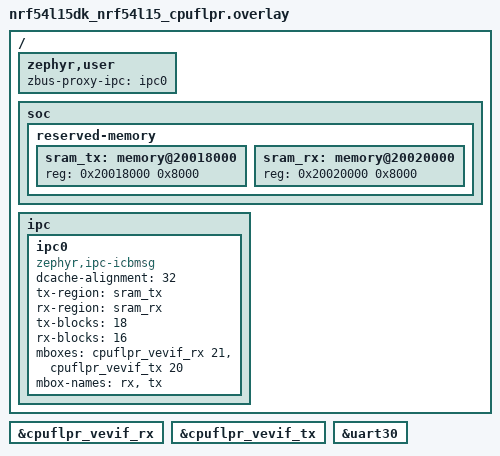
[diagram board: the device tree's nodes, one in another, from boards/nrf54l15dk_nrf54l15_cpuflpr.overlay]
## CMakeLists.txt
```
#
# Copyright (c) 2025 Nordic Semiconductor ASA
#
# SPDX-License-Identifier: Apache-2.0
#

cmake_minimum_required(VERSION 3.20.0)

find_package(Zephyr REQUIRED HINTS $ENV{ZEPHYR_BASE})
project(remote_cpurad)

# target_include_directories(app PRIVATE ${CMAKE_CURRENT_SOURCE_DIR}/../common)

zephyr_library_include_directories(
  src
  ../common
)

target_sources(app PRIVATE src/main.c)
```

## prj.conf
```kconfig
#
# Copyright (c) 2025 Nordic Semiconductor ASA
#
# SPDX-License-Identifier: Apache-2.0
#

CONFIG_LOG=y

CONFIG_TEST_RANDOM_GENERATOR=y

CONFIG_ZBUS=y
CONFIG_ZBUS_PROXY_AGENT=y

CONFIG_ZBUS_PROXY_AGENT_MESSAGE_SIZE=16
CONFIG_ZBUS_PROXY_AGENT_CHANNEL_NAME_SIZE=20

CONFIG_ZBUS_PROXY_AGENT_IPC=y
```

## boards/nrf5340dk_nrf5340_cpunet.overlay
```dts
/*
 * Copyright (c) 2025 Nordic Semiconductor ASA
 *
 * SPDX-License-Identifier: Apache-2.0
 */

/ {
	ipc_proxy_agent: ipc-proxy {
		compatible = "zephyr,zbus-proxy-agent-ipc";
		status = "okay";
		ipc-device = <&ipc0>;
	};
};
```

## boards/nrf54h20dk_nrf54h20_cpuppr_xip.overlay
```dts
/*
 * Copyright (c) 2025 Nordic Semiconductor ASA
 *
 * SPDX-License-Identifier: Apache-2.0
 */

&cpuapp_bellboard {
	status = "okay";
};

ipc0: &cpuapp_cpuppr_ipc {
	status = "okay";
};

&cpuppr_vevif {
	status = "okay";
};

/ {
	ipc_proxy_agent: ipc-proxy {
		compatible = "zephyr,zbus-proxy-agent-ipc";
		status = "okay";
		ipc-device = <&ipc0>;
	};

	chosen {
		/delete-property/ zephyr,bt-hci;
	};
};
```

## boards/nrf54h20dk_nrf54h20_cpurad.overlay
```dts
/*
 * Copyright (c) 2025 Nordic Semiconductor ASA
 *
 * SPDX-License-Identifier: Apache-2.0
 */

/ {
	zephyr,user {
		zbus-proxy-ipc = <&ipc0>;
	};
};
```

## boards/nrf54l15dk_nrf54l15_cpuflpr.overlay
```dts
/*
 * Copyright (c) 2025 Nordic Semiconductor ASA
 *
 * SPDX-License-Identifier: Apache-2.0
 */

/ {
	zephyr,user {
		zbus-proxy-ipc = <&ipc0>;
	};

	soc {
		reserved-memory {
			#address-cells = <1>;
			#size-cells = <1>;

			sram_tx: memory@20018000 {
				reg = <0x20018000 0x8000>;
			};

			sram_rx: memory@20020000 {
				reg = <0x20020000 0x8000>;
			};
		};
	};

	ipc {
		ipc0: ipc0 {
			compatible = "zephyr,ipc-icbmsg";
			dcache-alignment = <32>;
			tx-region = <&sram_tx>;
			rx-region = <&sram_rx>;
			tx-blocks = <18>;
			rx-blocks = <16>;
			mboxes = <&cpuflpr_vevif_rx 21>, <&cpuflpr_vevif_tx 20>;
			mbox-names = "rx", "tx";
			status = "okay";
		};
	};
};

&cpuflpr_vevif_rx {
	status = "okay";
};

&cpuflpr_vevif_tx {
	status = "okay";
};

&uart30 {
	/delete-property/ hw-flow-control;
};
```

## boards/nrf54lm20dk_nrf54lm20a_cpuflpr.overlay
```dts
/*
 * Copyright (c) 2025 Nordic Semiconductor ASA
 *
 * SPDX-License-Identifier: Apache-2.0
 */

/ {
	zephyr,user {
		zbus-proxy-ipc = <&ipc0>;
	};

	soc {
		reserved-memory {
			#address-cells = <1>;
			#size-cells = <1>;

			sram_tx: memory@20057c00 {
				reg = <0x20057c00 0x8000>;
			};

			sram_rx: memory@2005fc00 {
				reg = <0x2005fc00 0x8000>;
			};
		};
	};

	ipc {
		ipc0: ipc0 {
			compatible = "zephyr,ipc-icbmsg";
			dcache-alignment = <32>;
			tx-region = <&sram_tx>;
			rx-region = <&sram_rx>;
			tx-blocks = <18>;
			rx-blocks = <16>;
			mboxes = <&cpuflpr_vevif_rx 21>, <&cpuflpr_vevif_tx 20>;
			mbox-names = "rx", "tx";
			status = "okay";
		};
	};
};

&cpuflpr_vevif_rx {
	status = "okay";
};

&cpuflpr_vevif_tx {
	status = "okay";
};

&uart30 {
	/delete-property/ hw-flow-control;
};
```

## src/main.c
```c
/*
 * Copyright (c) 2025 Nordic Semiconductor ASA
 *
 * SPDX-License-Identifier: Apache-2.0
 */

#include <zephyr/kernel.h>
#include <zephyr/logging/log.h>
#include <zephyr/random/random.h>
#include <zephyr/zbus/zbus.h>
#include <zephyr/zbus/proxy_agent/zbus_proxy_agent.h>
#include <zephyr/zbus/proxy_agent/zbus_proxy_agent_ipc.h>

#include "common.h"

LOG_MODULE_REGISTER(main, LOG_LEVEL_DBG);

ZBUS_PROXY_AGENT_DEFINE(
	proxy_agent,                                    /* Proxy agent name */
	ZBUS_PROXY_AGENT_TYPE_IPC,                      /* Proxy agent type */
	DT_PROP(DT_PATH(zephyr_user), zbus_proxy_ipc),  /* Backend node */
	1,                                              /* Initial ack timeout ms */
	1,                                              /* Max transmit attempts */
	4                                               /* Max concurrent tracked messages */
)

/*
 * Channel definition
 * Channel request_channel is shadow channels, shadowing channel from domain A
 * Channel response_channel is origin channel, being forwarded to domain A
 */

ZBUS_SHADOW_CHAN_DEFINE(
	request_channel,      /* Chan name */
	struct request_data,  /* Message type */

	proxy_agent,          /* Proxy agent name */
	NULL,                 /* User data */
	ZBUS_OBSERVERS_EMPTY, /* Observers */
	ZBUS_MSG_INIT(0)      /* Initial value */
);

ZBUS_CHAN_DEFINE(
	response_channel,     /* Chan name */
	struct response_data, /* Message type */

	NULL,                 /* Validator function */
	NULL,                 /* User data */
	ZBUS_OBSERVERS_EMPTY, /* Observers */
	ZBUS_MSG_INIT(0)      /* Initial value */
);

ZBUS_PROXY_ADD_CHAN(proxy_agent, response_channel);

int get_random_value(int min, int max)
{
	return min + (sys_rand32_get() % (max - min + 1));
}

/* Listen for requests on the request channel, and respond on the response channel */
static void ipc_forwarder_listener_cb(const struct zbus_channel *chan)
{
	int ret;
	const struct request_data *data = zbus_chan_const_msg(chan);
	struct response_data response = {
		.response_id = data->request_id,
		.value = get_random_value(data->min_value, data->max_value)};

	LOG_INF("Received message on channel %s", chan->name);
	LOG_INF("Request ID: %d, Min: %d, Max: %d", data->request_id, data->min_value,
		data->max_value);

	LOG_INF("Sending response: ID=%d, Value=%d", response.response_id, response.value);

	ret = zbus_chan_pub(&response_channel, &response, K_MSEC(100));
	if (ret < 0) {
		LOG_ERR("Failed to publish response on channel %s: %d", response_channel.name, ret);
	} else {
		LOG_INF("Response published on channel %s", response_channel.name);
	}
}

ZBUS_LISTENER_DEFINE(ipc_forwarder_listener, ipc_forwarder_listener_cb);
ZBUS_CHAN_ADD_OBS(request_channel, ipc_forwarder_listener, 0);

int main(void)
{
	LOG_INF("ZBUS Proxy agent IPC Forwarder Sample Application");
	LOG_INF("Listening for requests on channel %s, responding on channel %s",
		request_channel.name, response_channel.name);

	return 0;
}
```
